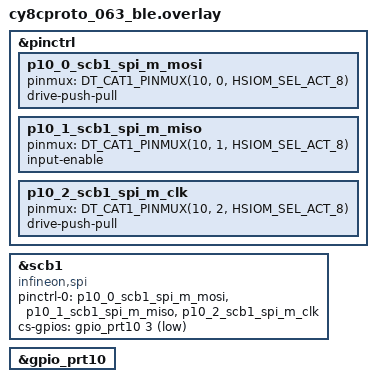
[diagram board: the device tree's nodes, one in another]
/*
 * SPDX-FileCopyrightText: Copyright The Zephyr Project Contributors
 *
 * SPDX-License-Identifier: Apache-2.0
 */

&pinctrl {
	/* Configure pin control bias mode for SPI pins (MASTER) */
	p10_0_scb1_spi_m_mosi: p10_0_scb1_spi_m_mosi {
		pinmux = <DT_CAT1_PINMUX(10, 0, HSIOM_SEL_ACT_8)>;
		drive-push-pull;
	};

	p10_1_scb1_spi_m_miso: p10_1_scb1_spi_m_miso {
		pinmux = <DT_CAT1_PINMUX(10, 1, HSIOM_SEL_ACT_8)>;
		input-enable;
	};

	p10_2_scb1_spi_m_clk: p10_2_scb1_spi_m_clk {
		pinmux = <DT_CAT1_PINMUX(10, 2, HSIOM_SEL_ACT_8)>;
		drive-push-pull;
	};
};

#define SPI_LOOPBACK_SLOW_HZ 200000
#define SPI_LOOPBACK_FAST_HZ 1500000

spi_loopback: &scb1 {
	compatible = "infineon,spi";
	status = "okay";

	pinctrl-0 = <&p10_0_scb1_spi_m_mosi &p10_1_scb1_spi_m_miso &p10_2_scb1_spi_m_clk>;
	pinctrl-names = "default";
	cs-gpios = <&gpio_prt10 3 GPIO_ACTIVE_LOW>;
};

&gpio_prt10 {
	status = "okay";
};

#include "../spi-loopback.dtsi"
